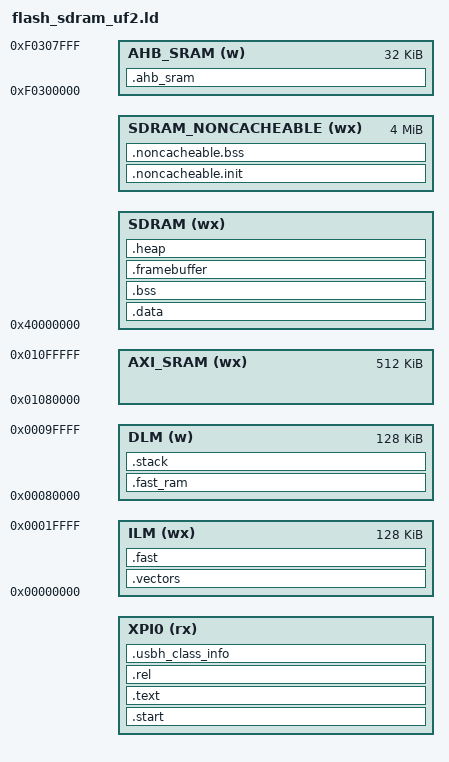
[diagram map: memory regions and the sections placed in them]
/*
 * Copyright (c) 2022-2023 HPMicro
 * SPDX-License-Identifier: BSD-3-Clause
 */

ENTRY(_start)

STACK_SIZE = DEFINED(_stack_size) ? _stack_size : 0x4000;
HEAP_SIZE = DEFINED(_heap_size) ? _heap_size : 0x4000;
UF2_BOOTLOADER_RESERVED_LENGTH = DEFINED(_uf2_bl_length) ? _uf2_bl_length : 0x20000;

MEMORY
{
    XPI0 (rx) : ORIGIN = 0x80000000 + UF2_BOOTLOADER_RESERVED_LENGTH, LENGTH = _flash_size - UF2_BOOTLOADER_RESERVED_LENGTH
    ILM (wx) : ORIGIN = 0x00000000, LENGTH = 128K
    DLM (w) : ORIGIN = 0x00080000, LENGTH = 128K
    AXI_SRAM (wx) : ORIGIN = 0x1080000, LENGTH = 512K
    SDRAM (wx) : ORIGIN = 0x40000000, LENGTH = (_extram_size - 4M)
    SDRAM_NONCACHEABLE (wx) : ORIGIN = 0x40000000 + (_extram_size - 4M), LENGTH = 4M
    AHB_SRAM (w) : ORIGIN = 0xF0300000, LENGTH = 32k
}

SECTIONS
{
    .start : {
        KEEP(*(.uf2_signature))
        KEEP(*(.start))
    } > XPI0

    .text (__vector_load_addr__ + __vector_ram_end__ - __vector_ram_start__): {
        . = ALIGN(8);
        *(.text)
        *(.text*)
        *(.rodata)
        *(.rodata*)
        *(.srodata)
        *(.srodata*)

        *(.hash)
        *(.dyn*)
        *(.gnu*)
        *(.pl*)

        KEEP(*(.eh_frame))
        *(.eh_frame*)

        KEEP (*(.init))
        KEEP (*(.fini))
        . = ALIGN(8);
    } > XPI0

    .rel : {
        KEEP(*(.rel*))
    } > XPI0

    /* section information for usbh class */
    .usbh_class_info : {
        . = ALIGN(4);
        __usbh_class_info_start__ = .;
        KEEP(*(.usbh_class_info))
        __usbh_class_info_end__ = .;
        . = ALIGN(8);
    } > XPI0

    PROVIDE (__etext = .);
    PROVIDE (_etext = .);
    PROVIDE (etext = .);

    __vector_load_addr__ = ADDR(.start) + SIZEOF(.start);
    .vectors ORIGIN(ILM) : AT(__vector_load_addr__) {
        . = ALIGN(8);
        __vector_ram_start__ = .;
        KEEP(*(.vector_table))
        KEEP(*(.isr_vector))
        KEEP(*(.vector_s_table))
        KEEP(*(.isr_s_vector))
        . = ALIGN(8);
        __vector_ram_end__ = .;
    } > ILM

    .data : AT(etext) {
        . = ALIGN(8);
        __data_start__ = .;
        __global_pointer$ = . + 0x800;
        *(.data)
        *(.data*)
        *(.sdata)
        *(.sdata*)
        *(.tdata)
        *(.tdata*)

        KEEP(*(.jcr))
        KEEP(*(.dynamic))
        KEEP(*(.got*))
        KEEP(*(.got))
        KEEP(*(.gcc_except_table))
        KEEP(*(.gcc_except_table.*))

        . = ALIGN(8);
        PROVIDE(__preinit_array_start = .);
        KEEP(*(.preinit_array))
        PROVIDE(__preinit_array_end = .);

        . = ALIGN(8);
        PROVIDE(__init_array_start = .);
        KEEP(*(SORT_BY_INIT_PRIORITY(.init_array.*)))
        KEEP(*(.init_array))
        PROVIDE(__init_array_end = .);

        . = ALIGN(8);
        PROVIDE(__finit_array_start = .);
        KEEP(*(SORT_BY_INIT_PRIORITY(.finit_array.*)))
        KEEP(*(.finit_array))
        PROVIDE(__finit_array_end = .);

        . = ALIGN(8);
        KEEP(*crtbegin*.o(.ctors))
        KEEP(*(EXCLUDE_FILE (*crtend*.o) .ctors))
        KEEP(*(SORT(.ctors.*)))
        KEEP(*(.ctors))

        . = ALIGN(8);
        KEEP(*crtbegin*.o(.dtors))
        KEEP(*(EXCLUDE_FILE (*crtend*.o) .dtors))
        KEEP(*(SORT(.dtors.*)))
        KEEP(*(.dtors))
        . = ALIGN(8);
        __data_end__ = .;
        PROVIDE (__edata = .);
        PROVIDE (_edata = .);
        PROVIDE (edata = .);
    } > SDRAM

    .fast : AT(etext + __data_end__ - __data_start__) {
        . = ALIGN(8);
        __ramfunc_start__ = .;
        *(.fast)
        . = ALIGN(8);
        __ramfunc_end__ = .;
    } > ILM

    .bss (NOLOAD) : {
        . = ALIGN(8);
        __bss_start__ = .;
        *(.bss)
        *(.bss*)
        *(.tbss*)
        *(.sbss*)
        *(.scommon)
        *(.scommon*)
        *(.tcommon*)
        *(.dynsbss*)
        *(COMMON)
        . = ALIGN(8);
        _end = .;
        __bss_end__ = .;
    } > SDRAM

    .framebuffer (NOLOAD) : {
        . = ALIGN(8);
        KEEP(*(.framebuffer))
        . = ALIGN(8);
    } > SDRAM

    .noncacheable.init : AT(etext + __data_end__ - __data_start__ + __ramfunc_end__ - __ramfunc_start__){
        . = ALIGN(8);
        __noncacheable_init_start__ = .;
        KEEP(*(.noncacheable.init))
        __noncacheable_init_end__ = .;
        . = ALIGN(8);
    } > SDRAM_NONCACHEABLE

    .noncacheable.bss (NOLOAD) : {
        . = ALIGN(8);
        KEEP(*(.noncacheable))
        __noncacheable_bss_start__ = .;
        KEEP(*(.noncacheable.bss))
        __noncacheable_bss_end__ = .;
        . = ALIGN(8);
    } > SDRAM_NONCACHEABLE

    .ahb_sram (NOLOAD) : {
        KEEP(*(.ahb_sram))
    } > AHB_SRAM

    .fast_ram (NOLOAD) : {
        KEEP(*(.fast_ram))
    } > DLM

    .heap (NOLOAD) : {
        . = ALIGN(8);
        __heap_start__ = .;
        . += HEAP_SIZE;
        __heap_end__ = .;
    } > SDRAM

    .stack (NOLOAD) : {
        . = ALIGN(8);
        __stack_base__ = .;
        . += STACK_SIZE;
        . = ALIGN(8);
        PROVIDE (_stack = .);
        PROVIDE (_stack_safe = .);
    } > DLM

    __noncacheable_start__ = ORIGIN(SDRAM_NONCACHEABLE);
    __noncacheable_end__ = ORIGIN(SDRAM_NONCACHEABLE) + LENGTH(SDRAM_NONCACHEABLE);
}
